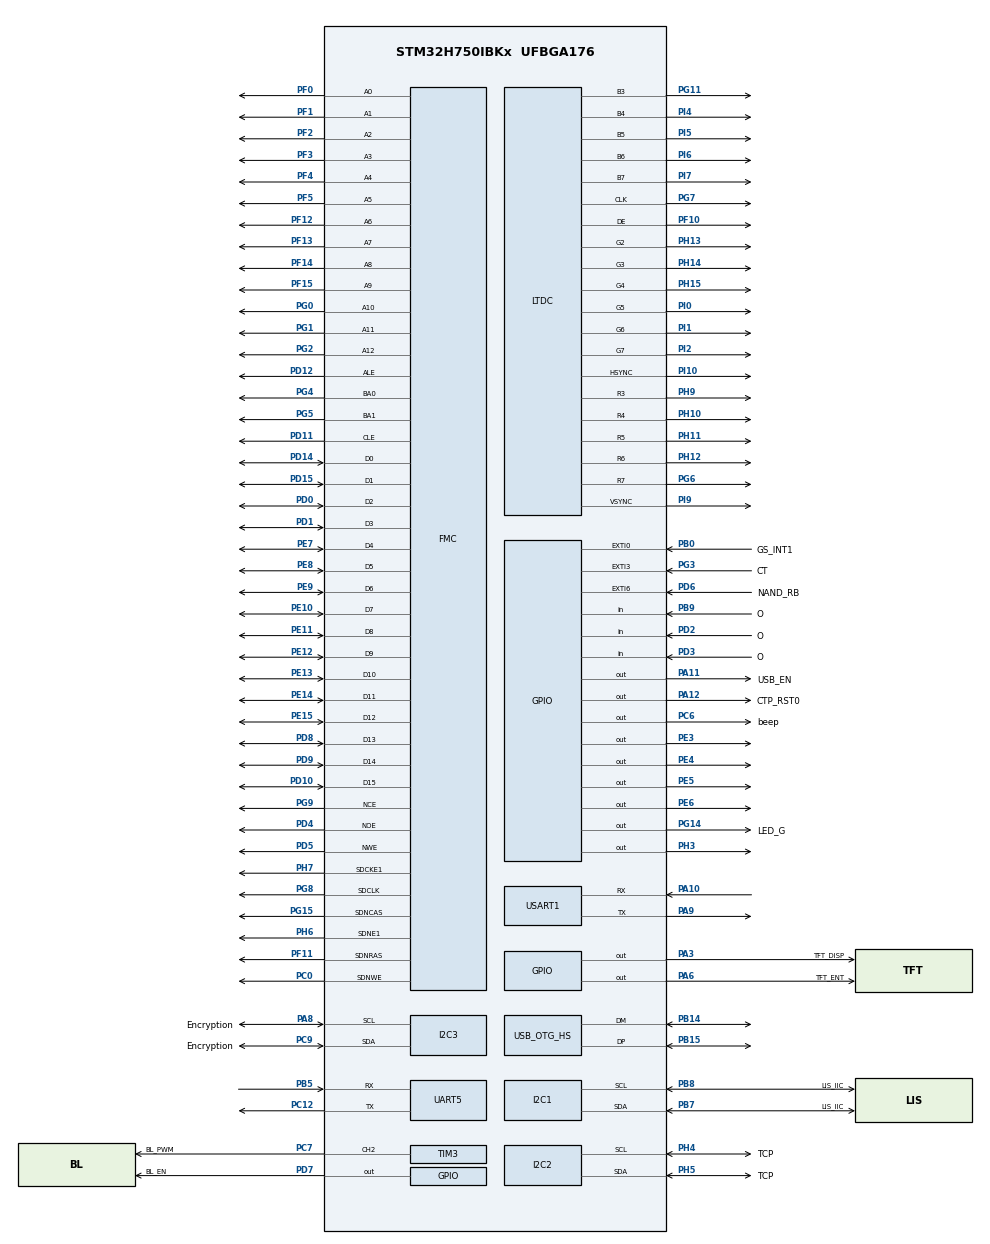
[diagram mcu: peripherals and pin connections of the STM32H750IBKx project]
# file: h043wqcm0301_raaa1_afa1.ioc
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CORTEX_M7.BaseAddress-Cortex_Memory_Protection_Unit_Region0_Settings=0x24000000
CORTEX_M7.BaseAddress-Cortex_Memory_Protection_Unit_Region1_Settings=0x30000000
CORTEX_M7.BaseAddress-Cortex_Memory_Protection_Unit_Region2_Settings=0x80000000
CORTEX_M7.BaseAddress-Cortex_Memory_Protection_Unit_Region3_Settings=0xD0000000
CORTEX_M7.CPU_DCache=Enabled
CORTEX_M7.CPU_ICache=Enabled
CORTEX_M7.Enable-Cortex_Memory_Protection_Unit_Region0_Settings=MPU_REGION_ENABLE
CORTEX_M7.Enable-Cortex_Memory_Protection_Unit_Region1_Settings=MPU_REGION_ENABLE
CORTEX_M7.Enable-Cortex_Memory_Protection_Unit_Region2_Settings=MPU_REGION_ENABLE
CORTEX_M7.Enable-Cortex_Memory_Protection_Unit_Region3_Settings=MPU_REGION_ENABLE
CORTEX_M7.IsBufferable-Cortex_Memory_Protection_Unit_Region0_Settings=MPU_ACCESS_BUFFERABLE
CORTEX_M7.IsBufferable-Cortex_Memory_Protection_Unit_Region1_Settings=MPU_ACCESS_BUFFERABLE
CORTEX_M7.IsBufferable-Cortex_Memory_Protection_Unit_Region2_Settings=MPU_ACCESS_BUFFERABLE
CORTEX_M7.IsBufferable-Cortex_Memory_Protection_Unit_Region3_Settings=MPU_ACCESS_BUFFERABLE
CORTEX_M7.IsCacheable-Cortex_Memory_Protection_Unit_Region0_Settings=MPU_ACCESS_CACHEABLE
CORTEX_M7.IsCacheable-Cortex_Memory_Protection_Unit_Region1_Settings=MPU_ACCESS_CACHEABLE
CORTEX_M7.IsCacheable-Cortex_Memory_Protection_Unit_Region2_Settings=MPU_ACCESS_CACHEABLE
CORTEX_M7.IsCacheable-Cortex_Memory_Protection_Unit_Region3_Settings=MPU_ACCESS_CACHEABLE
CORTEX_M7.IsShareable-Cortex_Memory_Protection_Unit_Region0_Settings=MPU_ACCESS_NOT_SHAREABLE
CORTEX_M7.MPU_Control=MPU_PRIVILEGED_DEFAULT
CORTEX_M7.Size-Cortex_Memory_Protection_Unit_Region0_Settings=MPU_REGION_SIZE_512KB
CORTEX_M7.Size-Cortex_Memory_Protection_Unit_Region1_Settings=MPU_REGION_SIZE_256B
CORTEX_M7.Size-Cortex_Memory_Protection_Unit_Region2_Settings=MPU_REGION_SIZE_256MB
CORTEX_M7.Size-Cortex_Memory_Protection_Unit_Region3_Settings=MPU_REGION_SIZE_32MB
DMA2D.ColorMode=DMA2D_OUTPUT_RGB565
DMA2D.InputAlphaForeground=255
FREERTOS.Tasks01=defaultTask,24,128,StartDefaultTask,Default,NULL,Dynamic,NULL,NULL
FREERTOS.configLIBRARY_MAX_SYSCALL_INTERRUPT_PRIORITY=1
FREERTOS.configTIMER_TASK_PRIORITY=0
FREERTOS.configTOTAL_HEAP_SIZE=15360
I2C1.Timing=0x307075B1
I2C2.Timing=0x307075B1
I2C3.Timing=0x307075B1
IWDG1.Prescaler=IWDG_PRESCALER_64
JPEG.JPEG_RGB_FORMAT=JPEG_RGB888
LTDC.ActiveH=272
LTDC.ActiveW=480
LTDC.Blue_L0=255
LTDC.FBStartAdress_L0=0xD0000000
LTDC.HBP=2
LTDC.HFP=2
LTDC.HSync=41
LTDC.ImageHeight_L0=272
LTDC.ImageWidth_L0=480
LTDC.Layers=0
LTDC.PixelFormat_L0=LTDC_PIXEL_FORMAT_RGB565
LTDC.VSync=10
LTDC.WindowX1_L0=480
LTDC.WindowX1_L1=480
LTDC.WindowY1_L0=272
LTDC.WindowY1_L1=272
Mcu.Family=STM32H7
Mcu.Name=STM32H750IBKx
Mcu.Package=UFBGA176
NVIC.DMA2D_IRQn=true\:14\:0\:true\:false\:true\:true\:true\:true
NVIC.EXTI0_IRQn=true\:15\:0\:true\:false\:true\:false\:true\:true
NVIC.EXTI3_IRQn=true\:15\:0\:true\:false\:true\:false\:true\:true
NVIC.EXTI9_5_IRQn=true\:15\:0\:true\:false\:true\:false\:true\:true
NVIC.LTDC_IRQn=true\:15\:0\:true\:false\:true\:false\:true\:true
NVIC.OTG_HS_IRQn=true\:5\:0\:true\:false\:true\:true\:false\:true
NVIC.PriorityGroup=NVIC_PRIORITYGROUP_4
NVIC.TIM6_DAC_IRQn=true\:0\:0\:false\:false\:true\:false\:false\:true
NVIC.TimeBase=TIM6_DAC_IRQn
NVIC.TimeBaseIP=TIM6
NVIC.UART5_IRQn=true\:6\:0\:true\:false\:true\:false\:true\:true
NVIC.USART1_IRQn=true\:6\:0\:true\:false\:true\:false\:true\:true
PA10.GPIO_Speed=GPIO_SPEED_FREQ_HIGH
PA10.Mode=Asynchronous
PA10.Signal=USART1_RX
PA11.GPIO_Label=USB_EN
PA11.GPIO_Speed=GPIO_SPEED_FREQ_HIGH
PA11.Signal=GPIO_Output
PA12.GPIO_Label=CTP_RST0
PA12.GPIO_PuPd=GPIO_PULLUP
PA12.GPIO_Speed=GPIO_SPEED_FREQ_HIGH
PA12.PinState=GPIO_PIN_SET
PA12.Signal=GPIO_Output
PA3.GPIO_Label=TFT_DISP
PA3.GPIO_PuPd=GPIO_PULLUP
PA3.GPIO_Speed=GPIO_SPEED_FREQ_HIGH
PA3.PinState=GPIO_PIN_SET
PA3.Signal=GPIO_Output
PA6.GPIO_Label=TFT_ENT
PA6.GPIO_PuPd=GPIO_PULLUP
PA6.GPIO_Speed=GPIO_SPEED_FREQ_HIGH
PA6.PinState=GPIO_PIN_SET
PA6.Signal=GPIO_Output
PA8.GPIO_Label=Encryption
PA8.GPIO_PuPd=GPIO_PULLUP
PA8.GPIO_Speed=GPIO_SPEED_FREQ_VERY_HIGH
PA8.Mode=I2C
PA8.Signal=I2C3_SCL
PA9.GPIO_Speed=GPIO_SPEED_FREQ_HIGH
PA9.Mode=Asynchronous
PA9.Signal=USART1_TX
PB0.GPIO_Label=GS_INT1
PB0.GPIO_ModeDefaultEXTI=GPIO_MODE_IT_FALLING
PB0.Signal=GPXTI0
PB14.GPIO_Speed=GPIO_SPEED_FREQ_HIGH
PB14.Mode=Host_FS
PB14.Signal=USB_OTG_HS_DM
PB15.GPIO_Speed=GPIO_SPEED_FREQ_HIGH
PB15.Mode=Host_FS
PB15.Signal=USB_OTG_HS_DP
PB5.GPIO_Speed=GPIO_SPEED_FREQ_VERY_HIGH
PB5.Mode=Asynchronous
PB5.Signal=UART5_RX
PB7.GPIO_FM7=__NULL
PB7.GPIO_Label=LIS_IIC
PB7.GPIO_PuPd=GPIO_PULLUP
PB7.GPIO_Speed=GPIO_SPEED_FREQ_VERY_HIGH
PB7.Mode=I2C
PB7.Signal=I2C1_SDA
PB8.GPIO_Label=LIS_IIC
PB8.GPIO_PuPd=GPIO_PULLUP
PB8.GPIO_Speed=GPIO_SPEED_FREQ_VERY_HIGH
PB8.Mode=I2C
PB8.Signal=I2C1_SCL
PB9.GPIO_Label=O
PB9.Signal=GPIO_Input
PC0.Signal=FMC_SDNWE
PC12.GPIO_Speed=GPIO_SPEED_FREQ_VERY_HIGH
PC12.Mode=Asynchronous
PC12.Signal=UART5_TX
PC14-OSC32_IN\ (OSC32_IN).Mode=LSE-External-Oscillator
PC14-OSC32_IN\ (OSC32_IN).Signal=RCC_OSC32_IN
PC15-OSC32_OUT\ (OSC32_OUT).Mode=LSE-External-Oscillator
PC15-OSC32_OUT\ (OSC32_OUT).Signal=RCC_OSC32_OUT
PC6.GPIO_Label=beep
PC6.GPIO_PuPd=GPIO_PULLDOWN
PC6.Signal=GPIO_Output
PC7.GPIO_Label=BL_PWM
PC7.GPIO_Speed=GPIO_SPEED_FREQ_VERY_HIGH
PC7.Signal=S_TIM3_CH2
PC9.GPIO_Label=Encryption
PC9.GPIO_PuPd=GPIO_PULLUP
PC9.GPIO_Speed=GPIO_SPEED_FREQ_VERY_HIGH
PC9.Mode=I2C
PC9.Signal=I2C3_SDA
PD0.Signal=FMC_D2_DA2
PD1.Signal=FMC_D3_DA3
PD10.Signal=FMC_D15_DA15
PD11.Signal=FMC_A16_CLE
PD12.Signal=FMC_A17_ALE
PD14.Signal=FMC_D0_DA0
PD15.Signal=FMC_D1_DA1
PD2.GPIO_Label=O
PD2.GPIO_PuPd=GPIO_NOPULL
PD2.Signal=GPIO_Input
PD3.GPIO_Label=O
PD3.Signal=GPIO_Input
PD4.Signal=FMC_NOE
PD5.Signal=FMC_NWE
PD6.GPIO_Label=NAND_RB
PD6.GPIO_ModeDefaultEXTI=GPIO_MODE_IT_FALLING
PD6.GPIO_PuPd=GPIO_NOPULL
PD6.Signal=GPXTI6
PD7.GPIO_Label=BL_EN
PD7.GPIO_PuPd=GPIO_PULLUP
PD7.GPIO_Speed=GPIO_SPEED_FREQ_HIGH
PD7.PinState=GPIO_PIN_SET
PD7.Signal=GPIO_Output
PD8.Signal=FMC_D13_DA13
PD9.Signal=FMC_D14_DA14
PE0.Signal=FMC_NBL0
PE1.Signal=FMC_NBL1
PE10.Signal=FMC_D7_DA7
PE11.Signal=FMC_D8_DA8
PE12.Signal=FMC_D9_DA9
PE13.Signal=FMC_D10_DA10
PE14.Signal=FMC_D11_DA11
PE15.Signal=FMC_D12_DA12
PE3.Signal=GPIO_Output
PE4.GPIO_PuPd=GPIO_PULLUP
PE4.GPIO_Speed=GPIO_SPEED_FREQ_HIGH
PE4.PinState=GPIO_PIN_SET
PE4.Signal=GPIO_Output
PE5.GPIO_PuPd=GPIO_PULLUP
PE5.GPIO_Speed=GPIO_SPEED_FREQ_HIGH
PE5.PinState=GPIO_PIN_SET
PE5.Signal=GPIO_Output
PE6.GPIO_PuPd=GPIO_PULLUP
PE6.GPIO_Speed=GPIO_SPEED_FREQ_HIGH
PE6.PinState=GPIO_PIN_SET
PE6.Signal=GPIO_Output
PE7.Signal=FMC_D4_DA4
PE8.Signal=FMC_D5_DA5
PE9.Signal=FMC_D6_DA6
PF0.Signal=FMC_A0
PF1.Signal=FMC_A1
PF10.Mode=RGB565
PF10.Signal=LTDC_DE
PF11.Signal=FMC_SDNRAS
PF12.Signal=FMC_A6
PF13.Signal=FMC_A7
PF14.Signal=FMC_A8
PF15.Signal=FMC_A9
PF2.Signal=FMC_A2
PF3.Signal=FMC_A3
PF4.Signal=FMC_A4
PF5.Signal=FMC_A5
PG0.Signal=FMC_A10
PG1.Signal=FMC_A11
PG11.Mode=RGB565
PG11.Signal=LTDC_B3
PG14.GPIO_Label=LED_G
PG14.GPIO_PuPd=GPIO_PULLUP
PG14.GPIO_Speed=GPIO_SPEED_FREQ_HIGH
PG14.Signal=GPIO_Output
PG15.Signal=FMC_SDNCAS
PG2.Signal=FMC_A12
PG3.GPIO_Label=CT
PG3.GPIO_ModeDefaultEXTI=GPIO_MODE_IT_FALLING
PG3.Signal=GPXTI3
PG4.Signal=FMC_A14_BA0
PG5.Signal=FMC_A15_BA1
PG6.Mode=RGB565
PG6.Signal=LTDC_R7
PG7.Mode=RGB565
PG7.Signal=LTDC_CLK
PG8.Signal=FMC_SDCLK
PG9.Mode=NandChipSelect3_1
PG9.Signal=FMC_NCE
PH0-OSC_IN\ (PH0).Mode=HSE-External-Oscillator
PH0-OSC_IN\ (PH0).Signal=RCC_OSC_IN
PH1-OSC_OUT\ (PH1).Mode=HSE-External-Oscillator
PH1-OSC_OUT\ (PH1).Signal=RCC_OSC_OUT
PH10.Mode=RGB565
PH10.Signal=LTDC_R4
PH11.Mode=RGB565
PH11.Signal=LTDC_R5
PH12.Mode=RGB565
PH12.Signal=LTDC_R6
PH13.Mode=RGB565
PH13.Signal=LTDC_G2
PH14.Mode=RGB565
PH14.Signal=LTDC_G3
PH15.Mode=RGB565
PH15.Signal=LTDC_G4
PH3.GPIO_PuPd=GPIO_PULLUP
PH3.GPIO_Speed=GPIO_SPEED_FREQ_VERY_HIGH
PH3.PinState=GPIO_PIN_SET
PH3.Signal=GPIO_Output
PH4.GPIO_Label=TCP
PH4.GPIO_PuPd=GPIO_PULLUP
PH4.GPIO_Speed=GPIO_SPEED_FREQ_VERY_HIGH
PH4.Mode=I2C
PH4.Signal=I2C2_SCL
PH5.GPIO_Label=TCP
PH5.GPIO_PuPd=GPIO_PULLUP
PH5.GPIO_Speed=GPIO_SPEED_FREQ_VERY_HIGH
PH5.Mode=I2C
PH5.Signal=I2C2_SDA
PH6.Mode=SdramChipSelect2_1
PH6.Signal=FMC_SDNE1
PH7.Mode=SdramChipSelect2_1
PH7.Signal=FMC_SDCKE1
PH9.Mode=RGB565
PH9.Signal=LTDC_R3
PI0.Mode=RGB565
PI0.Signal=LTDC_G5
PI1.Mode=RGB565
PI1.Signal=LTDC_G6
PI10.Mode=RGB565
PI10.Signal=LTDC_HSYNC
PI2.Mode=RGB565
PI2.Signal=LTDC_G7
PI4.Mode=RGB565
PI4.Signal=LTDC_B4
PI5.Mode=RGB565
PI5.Signal=LTDC_B5
PI6.Mode=RGB565
PI6.Signal=LTDC_B6
PI7.Mode=RGB565
PI7.Signal=LTDC_B7
PI9.Mode=RGB565
PI9.Signal=LTDC_VSYNC
ProjectManager.HeapSize=0x200
ProjectManager.StackSize=0x400
ProjectManager.TargetToolchain=STM32CubeIDE
RCC.ADCFreq_Value=50390625
RCC.APB1Freq_Value=120000000
RCC.APB2Freq_Value=120000000
RCC.APB3Freq_Value=120000000
RCC.APB4Freq_Value=120000000
RCC.CortexFreq_Value=480000000
RCC.D1PPRE=RCC_APB3_DIV2
RCC.D2PPRE1=RCC_APB1_DIV2
RCC.D2PPRE2=RCC_APB2_DIV2
RCC.D3PPRE=RCC_APB4_DIV2
RCC.DIVM1=5
RCC.DIVN1=192
RCC.DIVN3=192
RCC.DIVQ1=20
RCC.HCLKFreq_Value=240000000
RCC.HPRE=RCC_HCLK_DIV2
RCC.PLL2FRACN=0
RCC.PLL3FRACN=0
RCC.PLLFRACN=0
RCC.SYSCLKFreq_VALUE=480000000
RCC.SYSCLKSource=RCC_SYSCLKSOURCE_PLLCLK
RCC.USBFreq_Value=48000000
RTC.Format=RTC_FORMAT_BIN
RTC.Hours=8
SH.FMC_A0.0=FMC_A0,13b-sda1
SH.FMC_A1.0=FMC_A1,13b-sda1
SH.FMC_A10.0=FMC_A10,13b-sda1
SH.FMC_A11.0=FMC_A11,13b-sda1
SH.FMC_A12.0=FMC_A12,13b-sda1
SH.FMC_A14_BA0.0=FMC_BA0,FourSdramBanks1
SH.FMC_A15_BA1.0=FMC_BA1,FourSdramBanks1
SH.FMC_A16_CLE.0=FMC_CLE,8b-dmux1
SH.FMC_A17_ALE.0=FMC_ALE,8b-dmux1
SH.FMC_A2.0=FMC_A2,13b-sda1
SH.FMC_A3.0=FMC_A3,13b-sda1
SH.FMC_A4.0=FMC_A4,13b-sda1
SH.FMC_A5.0=FMC_A5,13b-sda1
SH.FMC_A6.0=FMC_A6,13b-sda1
SH.FMC_A7.0=FMC_A7,13b-sda1
SH.FMC_A8.0=FMC_A8,13b-sda1
SH.FMC_A9.0=FMC_A9,13b-sda1
SH.FMC_D0_DA0.0=FMC_D0,8b-dmux1
SH.FMC_D0_DA0.1=FMC_D0,sd-16b-d1
SH.FMC_D10_DA10.0=FMC_D10,sd-16b-d1
SH.FMC_D11_DA11.0=FMC_D11,sd-16b-d1
SH.FMC_D12_DA12.0=FMC_D12,sd-16b-d1
SH.FMC_D13_DA13.0=FMC_D13,sd-16b-d1
SH.FMC_D14_DA14.0=FMC_D14,sd-16b-d1
SH.FMC_D15_DA15.0=FMC_D15,sd-16b-d1
SH.FMC_D1_DA1.0=FMC_D1,8b-dmux1
SH.FMC_D1_DA1.1=FMC_D1,sd-16b-d1
SH.FMC_D2_DA2.0=FMC_D2,8b-dmux1
SH.FMC_D2_DA2.1=FMC_D2,sd-16b-d1
SH.FMC_D3_DA3.0=FMC_D3,8b-dmux1
SH.FMC_D3_DA3.1=FMC_D3,sd-16b-d1
SH.FMC_D4_DA4.0=FMC_D4,8b-dmux1
SH.FMC_D4_DA4.1=FMC_D4,sd-16b-d1
SH.FMC_D5_DA5.0=FMC_D5,8b-dmux1
SH.FMC_D5_DA5.1=FMC_D5,sd-16b-d1
SH.FMC_D6_DA6.0=FMC_D6,8b-dmux1
SH.FMC_D6_DA6.1=FMC_D6,sd-16b-d1
SH.FMC_D7_DA7.0=FMC_D7,8b-dmux1
SH.FMC_D7_DA7.1=FMC_D7,sd-16b-d1
SH.FMC_D8_DA8.0=FMC_D8,sd-16b-d1
SH.FMC_D9_DA9.0=FMC_D9,sd-16b-d1
SH.FMC_NBL0.0=FMC_NBL0
SH.FMC_NBL1.0=FMC_NBL1
SH.FMC_NOE.0=FMC_NOE,8b-dmux1
SH.FMC_NWE.0=FMC_NWE,8b-dmux1
SH.FMC_SDCLK.0=FMC_SDCLK,13b-sda1
SH.FMC_SDNCAS.0=FMC_SDNCAS,13b-sda1
SH.FMC_SDNRAS.0=FMC_SDNRAS,13b-sda1
SH.FMC_SDNWE.0=FMC_SDNWE,13b-sda1
SH.S_TIM3_CH2.0=TIM3_CH2,Output Compare2 CH2
TIM3.Channel-Output\ Compare2\ CH2=TIM_CHANNEL_2
USART1.VirtualMode-Asynchronous=VM_ASYNC
USB_HOST.BSP.number=1
USB_HOST.USBH_HandleTypeDef-MSC_HS=hUsbHostHS
USB_HOST.VirtualModeHS=Msc
USB_HOST0.BSP.STBoard=false
USB_HOST0.BSP.api=Unknown
USB_HOST0.BSP.i2caddr=0
USB_HOST0.BSP.instance=PA11
USB_HOST0.BSP.ip=GPIO
USB_HOST0.BSP.mode=Output
USB_HOST0.BSP.name=Drive_VBUS_HS
USB_HOST0.BSP.solution=PA11
USB_OTG_HS.VirtualMode-Host_FS=Host_FS
VP_DMA2D_VS_DMA2D.Mode=DMA2D_Activate
VP_FATFS_VS_USB.Mode=USB
VP_FREERTOS_VS_CMSIS_V2.Mode=CMSIS_V2
VP_IWDG1_VS_IWDG.Mode=IWDG_Activate
VP_JPEG_VS_JPEG.Mode=JPEG_Activate
VP_RTC_VS_RTC_Activate.Mode=RTC_Enabled
VP_RTC_VS_RTC_Calendar.Mode=RTC_Calendar
VP_SYS_VS_tim6.Mode=TIM6
VP_TIM3_VS_ClockSourceINT.Mode=Internal
VP_USB_HOST_VS_USB_HOST_MSC_HS.Mode=MSC_HS
board=custom

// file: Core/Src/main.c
/* USER CODE BEGIN Header */
/**
  ******************************************************************************
  * @file           : main.c
  * @brief          : Main program body
  ******************************************************************************
  * @attention
  *
  * <h2><center>&copy; Copyright (c) 2021 STMicroelectronics.
  * All rights reserved.</center></h2>
  *
  * This software component is licensed by ST under Ultimate Liberty license
  * SLA0044, the "License"; You may not use this file except in compliance with
  * the License. You may obtain a copy of the License at:
  *                             www.st.com/SLA0044
  *
  ******************************************************************************
  */
/* USER CODE END Header */
#include "main.h"
#include "cmsis_os.h"
#include "dma2d.h"
#include "fatfs.h"
#include "i2c.h"
#include "iwdg.h"
#include "jpeg.h"
#include "ltdc.h"
#include "rtc.h"
#include "tim.h"
#include "usart.h"
#include "usb_host.h"
#include "gpio.h"
#include "fmc.h"

/* USER CODE BEGIN Includes */

//#include"SDRAM_W98N_32M_16BIT.h"
//#include "display.h"
//#include "mem_my.h"
//#include "scif.h"

/* USER CODE END Includes */

void SystemClock_Config(void);
static void MPU_Config(void);
void MX_FREERTOS_Init(void);

int main(void)
{

  /* MPU Configuration--------------------------------------------------------*/
  MPU_Config();

  /* Enable I-Cache---------------------------------------------------------*/
  SCB_EnableICache();

  /* Enable D-Cache---------------------------------------------------------*/
  SCB_EnableDCache();

  /* MCU Configuration--------------------------------------------------------*/

  /* Reset of all peripherals, Initializes the Flash interface and the Systick. */
  HAL_Init();

  /* Configure the system clock */
  SystemClock_Config();

  /* Initialize all configured peripherals */
  MX_GPIO_Init();
  MX_FMC_Init();
  MX_FATFS_Init();
  MX_UART5_Init();
  MX_USART1_UART_Init();
  MX_DMA2D_Init();
  MX_I2C1_Init();
  MX_I2C2_Init();
  MX_I2C3_Init();
  MX_JPEG_Init();
  MX_LTDC_Init();
  MX_RTC_Init();
  MX_TIM3_Init();
  MX_IWDG1_Init();
  /* USER CODE BEGIN 2 */

//  init_memory((void *) MEM_BASE_ADDR,MALLOC_MEM_SIZE);
//  SDRAM_Initialization_Sequence(&hsdram1);
//  disp_dev.init();
  //usart_init(g_project->baudrate);

  /* USER CODE END 2 */

  /* Init scheduler */
  osKernelInitialize();  /* Call init function for freertos objects (in freertos.c) */
  MX_FREERTOS_Init();
  /* Start scheduler */
  osKernelStart();

  /* We should never get here as control is now taken by the scheduler */
  /* Infinite loop */
  while (1)
  {

  }
}

void SystemClock_Config(void)
{
  RCC_OscInitTypeDef RCC_OscInitStruct = {0};
  RCC_ClkInitTypeDef RCC_ClkInitStruct = {0};
  RCC_PeriphCLKInitTypeDef PeriphClkInitStruct = {0};

  /** Supply configuration update enable
  */
  HAL_PWREx_ConfigSupply(PWR_LDO_SUPPLY);
  /** Configure the main internal regulator output voltage
  */
  __HAL_PWR_VOLTAGESCALING_CONFIG(PWR_REGULATOR_VOLTAGE_SCALE0);

  while(!__HAL_PWR_GET_FLAG(PWR_FLAG_VOSRDY)) {}
  /** Macro to configure the PLL clock source
  */
  __HAL_RCC_PLL_PLLSOURCE_CONFIG(RCC_PLLSOURCE_HSE);
  /** Initializes the RCC Oscillators according to the specified parameters
  * in the RCC_OscInitTypeDef structure.
  */
  RCC_OscInitStruct.OscillatorType = RCC_OSCILLATORTYPE_LSI|RCC_OSCILLATORTYPE_HSE;
  RCC_OscInitStruct.HSEState = RCC_HSE_ON;
  RCC_OscInitStruct.LSIState = RCC_LSI_ON;
  RCC_OscInitStruct.PLL.PLLState = RCC_PLL_ON;
  RCC_OscInitStruct.PLL.PLLSource = RCC_PLLSOURCE_HSE;
  RCC_OscInitStruct.PLL.PLLM = 5;
  RCC_OscInitStruct.PLL.PLLN = 192;
  RCC_OscInitStruct.PLL.PLLP = 2;
  RCC_OscInitStruct.PLL.PLLQ = 20;
  RCC_OscInitStruct.PLL.PLLR = 2;
  RCC_OscInitStruct.PLL.PLLRGE = RCC_PLL1VCIRANGE_2;
  RCC_OscInitStruct.PLL.PLLVCOSEL = RCC_PLL1VCOWIDE;
  RCC_OscInitStruct.PLL.PLLFRACN = 0;
  if (HAL_RCC_OscConfig(&RCC_OscInitStruct) != HAL_OK)
  {
    Error_Handler();
  }
  /** Initializes the CPU, AHB and APB buses clocks
  */
  RCC_ClkInitStruct.ClockType = RCC_CLOCKTYPE_HCLK|RCC_CLOCKTYPE_SYSCLK
                              |RCC_CLOCKTYPE_PCLK1|RCC_CLOCKTYPE_PCLK2
                              |RCC_CLOCKTYPE_D3PCLK1|RCC_CLOCKTYPE_D1PCLK1;
  RCC_ClkInitStruct.SYSCLKSource = RCC_SYSCLKSOURCE_PLLCLK;
  RCC_ClkInitStruct.SYSCLKDivider = RCC_SYSCLK_DIV1;
  RCC_ClkInitStruct.AHBCLKDivider = RCC_HCLK_DIV2;
  RCC_ClkInitStruct.APB3CLKDivider = RCC_APB3_DIV2;
  RCC_ClkInitStruct.APB1CLKDivider = RCC_APB1_DIV2;
  RCC_ClkInitStruct.APB2CLKDivider = RCC_APB2_DIV2;
  RCC_ClkInitStruct.APB4CLKDivider = RCC_APB4_DIV2;

  if (HAL_RCC_ClockConfig(&RCC_ClkInitStruct, FLASH_LATENCY_4) != HAL_OK)
  {
    Error_Handler();
  }
  PeriphClkInitStruct.PeriphClockSelection = RCC_PERIPHCLK_RTC|RCC_PERIPHCLK_LTDC
                              |RCC_PERIPHCLK_USART1|RCC_PERIPHCLK_UART5
                              |RCC_PERIPHCLK_I2C2|RCC_PERIPHCLK_I2C3
                              |RCC_PERIPHCLK_I2C1|RCC_PERIPHCLK_USB
                              |RCC_PERIPHCLK_FMC;
  PeriphClkInitStruct.PLL3.PLL3M = 32;
  PeriphClkInitStruct.PLL3.PLL3N = 192;
  PeriphClkInitStruct.PLL3.PLL3P = 2;
  PeriphClkInitStruct.PLL3.PLL3Q = 2;
  PeriphClkInitStruct.PLL3.PLL3R = 2;
  PeriphClkInitStruct.PLL3.PLL3RGE = RCC_PLL3VCIRANGE_3;
  PeriphClkInitStruct.PLL3.PLL3VCOSEL = RCC_PLL3VCOMEDIUM;
  PeriphClkInitStruct.PLL3.PLL3FRACN = 0;
  PeriphClkInitStruct.FmcClockSelection = RCC_FMCCLKSOURCE_D1HCLK;
  PeriphClkInitStruct.Usart234578ClockSelection = RCC_USART234578CLKSOURCE_D2PCLK1;
  PeriphClkInitStruct.Usart16ClockSelection = RCC_USART16CLKSOURCE_D2PCLK2;
  PeriphClkInitStruct.I2c123ClockSelection = RCC_I2C123CLKSOURCE_D2PCLK1;
  PeriphClkInitStruct.UsbClockSelection = RCC_USBCLKSOURCE_PLL;
  PeriphClkInitStruct.RTCClockSelection = RCC_RTCCLKSOURCE_LSI;
  if (HAL_RCCEx_PeriphCLKConfig(&PeriphClkInitStruct) != HAL_OK)
  {
    Error_Handler();
  }
  /** Enable USB Voltage detector
  */
  HAL_PWREx_EnableUSBVoltageDetector();
}

/* MPU Configuration */

void MPU_Config(void)
{
  MPU_Region_InitTypeDef MPU_InitStruct = {0};

  /* Disables the MPU */
  HAL_MPU_Disable();
  /** Initializes and configures the Region and the memory to be protected
  */
  MPU_InitStruct.Enable = MPU_REGION_ENABLE;
  MPU_InitStruct.Number = MPU_REGION_NUMBER0;
  MPU_InitStruct.BaseAddress = 0x24000000;
  MPU_InitStruct.Size = MPU_REGION_SIZE_512KB;
  MPU_InitStruct.SubRegionDisable = 0x0;
  MPU_InitStruct.TypeExtField = MPU_TEX_LEVEL0;
  MPU_InitStruct.AccessPermission = MPU_REGION_NO_ACCESS;
  MPU_InitStruct.DisableExec = MPU_INSTRUCTION_ACCESS_ENABLE;
  MPU_InitStruct.IsShareable = MPU_ACCESS_NOT_SHAREABLE;
  MPU_InitStruct.IsCacheable = MPU_ACCESS_CACHEABLE;
  MPU_InitStruct.IsBufferable = MPU_ACCESS_BUFFERABLE;

  HAL_MPU_ConfigRegion(&MPU_InitStruct);
  /** Initializes and configures the Region and the memory to be protected
  */
  MPU_InitStruct.Enable = MPU_REGION_ENABLE;
  MPU_InitStruct.Number = MPU_REGION_NUMBER1;
  MPU_InitStruct.BaseAddress = 0x30000000;
  MPU_InitStruct.Size = MPU_REGION_SIZE_256B;
  MPU_InitStruct.SubRegionDisable = 0x0;
  MPU_InitStruct.TypeExtField = MPU_TEX_LEVEL0;
  MPU_InitStruct.AccessPermission = MPU_REGION_NO_ACCESS;
  MPU_InitStruct.DisableExec = MPU_INSTRUCTION_ACCESS_ENABLE;
  MPU_InitStruct.IsShareable = MPU_ACCESS_NOT_SHAREABLE;
  MPU_InitStruct.IsCacheable = MPU_ACCESS_CACHEABLE;
  MPU_InitStruct.IsBufferable = MPU_ACCESS_BUFFERABLE;

  HAL_MPU_ConfigRegion(&MPU_InitStruct);
  /** Initializes and configures the Region and the memory to be protected
  */
  MPU_InitStruct.Enable = MPU_REGION_ENABLE;
  MPU_InitStruct.Number = MPU_REGION_NUMBER2;
  MPU_InitStruct.BaseAddress = 0x80000000;
  MPU_InitStruct.Size = MPU_REGION_SIZE_256MB;
  MPU_InitStruct.SubRegionDisable = 0x0;
  MPU_InitStruct.TypeExtField = MPU_TEX_LEVEL0;
  MPU_InitStruct.AccessPermission = MPU_REGION_NO_ACCESS;
  MPU_InitStruct.DisableExec = MPU_INSTRUCTION_ACCESS_ENABLE;
  MPU_InitStruct.IsShareable = MPU_ACCESS_NOT_SHAREABLE;
  MPU_InitStruct.IsCacheable = MPU_ACCESS_CACHEABLE;
  MPU_InitStruct.IsBufferable = MPU_ACCESS_BUFFERABLE;

  HAL_MPU_ConfigRegion(&MPU_InitStruct);
  /** Initializes and configures the Region and the memory to be protected
  */
  MPU_InitStruct.Enable = MPU_REGION_ENABLE;
  MPU_InitStruct.Number = MPU_REGION_NUMBER3;
  MPU_InitStruct.BaseAddress = 0xD0000000;
  MPU_InitStruct.Size = MPU_REGION_SIZE_32MB;
  MPU_InitStruct.SubRegionDisable = 0x0;
  MPU_InitStruct.TypeExtField = MPU_TEX_LEVEL0;
  MPU_InitStruct.AccessPermission = MPU_REGION_NO_ACCESS;
  MPU_InitStruct.DisableExec = MPU_INSTRUCTION_ACCESS_ENABLE;
  MPU_InitStruct.IsShareable = MPU_ACCESS_NOT_SHAREABLE;
  MPU_InitStruct.IsCacheable = MPU_ACCESS_CACHEABLE;
  MPU_InitStruct.IsBufferable = MPU_ACCESS_BUFFERABLE;

  HAL_MPU_ConfigRegion(&MPU_InitStruct);
  /* Enables the MPU */
  HAL_MPU_Enable(MPU_PRIVILEGED_DEFAULT);

}
void HAL_TIM_PeriodElapsedCallback(TIM_HandleTypeDef *htim)
{
  if (htim->Instance == TIM6) {
    HAL_IncTick();
  }
}

void Error_Handler(void)
{
  __disable_irq();
  while (1)
  {
  }
}

/************************ (C) COPYRIGHT STMicroelectronics *****END OF FILE****/

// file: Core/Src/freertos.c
/* USER CODE BEGIN Header */
/**
  ******************************************************************************
  * File Name          : freertos.c
  * Description        : Code for freertos applications
  ******************************************************************************
  * @attention
  *
  * <h2><center>&copy; Copyright (c) 2021 STMicroelectronics.
  * All rights reserved.</center></h2>
  *
  * This software component is licensed by ST under Ultimate Liberty license
  * SLA0044, the "License"; You may not use this file except in compliance with
  * the License. You may obtain a copy of the License at:
  *                             www.st.com/SLA0044
  *
  ******************************************************************************
  */
/* USER CODE END Header */

#include "FreeRTOS.h"
#include "task.h"
#include "main.h"
#include "cmsis_os.h"

/* Definitions for defaultTask */
osThreadId_t defaultTaskHandle;
const osThreadAttr_t defaultTask_attributes = {
  .name = "defaultTask",
  .priority = (osPriority_t) osPriorityNormal,
  .stack_size = 128 * 4
};

void StartDefaultTask(void *argument);

extern void MX_USB_HOST_Init(void);
void MX_FREERTOS_Init(void); /* (MISRA C 2004 rule 8.1) */

void MX_FREERTOS_Init(void) {

  /* Create the thread(s) */
  /* creation of defaultTask */
  defaultTaskHandle = osThreadNew(StartDefaultTask, NULL, &defaultTask_attributes);

}

void StartDefaultTask(void *argument)
{
  /* init code for USB_HOST */
  MX_USB_HOST_Init();
  for(;;)
  {
    osDelay(1);
  }
}

/************************ (C) COPYRIGHT STMicroelectronics *****END OF FILE****/
